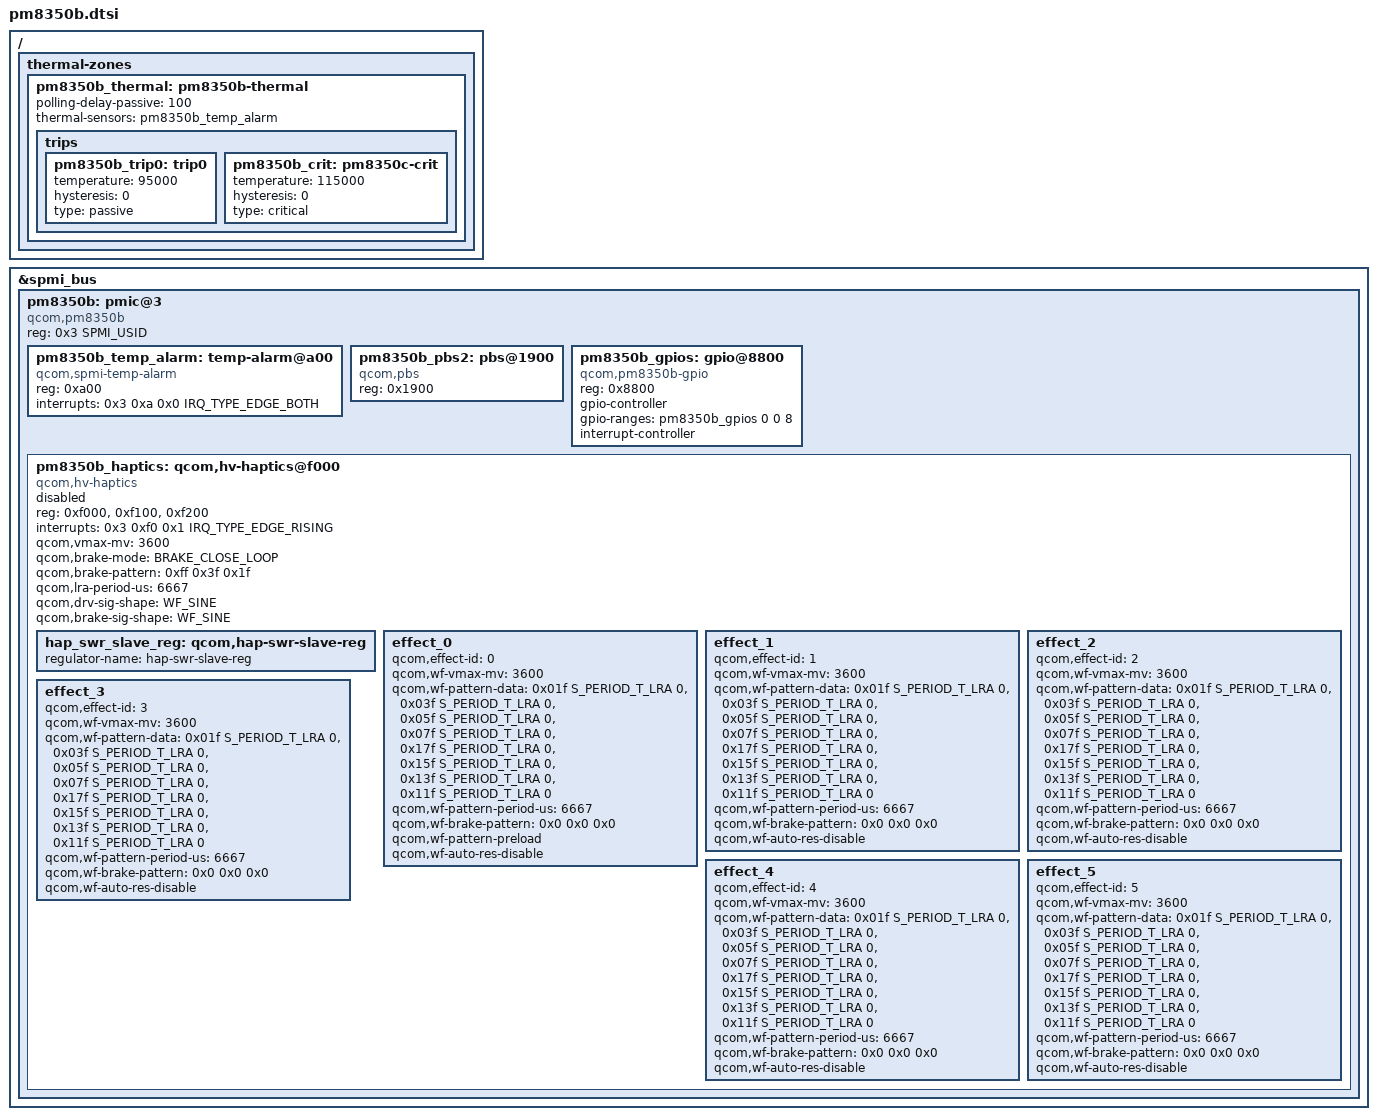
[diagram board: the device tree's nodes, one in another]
// SPDX-License-Identifier: BSD-3-Clause
/*
 * Copyright (c) 2021, Linaro Limited
 */

#include <dt-bindings/interrupt-controller/irq.h>
#include <dt-bindings/spmi/spmi.h>
#include <dt-bindings/input/qcom,hv-haptics.h>

/ {
	thermal-zones {
		pm8350b_thermal: pm8350b-thermal {
			polling-delay-passive = <100>;

			thermal-sensors = <&pm8350b_temp_alarm>;

			trips {
				pm8350b_trip0: trip0 {
					temperature = <95000>;
					hysteresis = <0>;
					type = "passive";
				};

				pm8350b_crit: pm8350c-crit {
					temperature = <115000>;
					hysteresis = <0>;
					type = "critical";
				};
			};
		};
	};
};

&spmi_bus {
	pm8350b: pmic@3 {
		compatible = "qcom,pm8350b", "qcom,spmi-pmic";
		reg = <0x3 SPMI_USID>;
		#address-cells = <1>;
		#size-cells = <0>;

		pm8350b_temp_alarm: temp-alarm@a00 {
			compatible = "qcom,spmi-temp-alarm";
			reg = <0xa00>;
			interrupts = <0x3 0xa 0x0 IRQ_TYPE_EDGE_BOTH>;
			#thermal-sensor-cells = <0>;
		};

		pm8350b_pbs2: pbs@1900 {
			compatible = "qcom,pbs";
			reg = <0x1900>;
		};

		pm8350b_gpios: gpio@8800 {
			compatible = "qcom,pm8350b-gpio", "qcom,spmi-gpio";
			reg = <0x8800>;
			gpio-controller;
			gpio-ranges = <&pm8350b_gpios 0 0 8>;
			#gpio-cells = <2>;
			interrupt-controller;
			#interrupt-cells = <2>;
		};

		pm8350b_haptics: qcom,hv-haptics@f000 {
			compatible = "qcom,hv-haptics";
			reg = <0xf000>, <0xf100>, <0xf200>;
			interrupts = <0x3 0xf0 0x1 IRQ_TYPE_EDGE_RISING>;
			interrupt-names = "fifo-empty";
			qcom,vmax-mv = <3600>;
			qcom,brake-mode = <BRAKE_CLOSE_LOOP>;
			qcom,brake-pattern = /bits/ 8 <0xff 0x3f 0x1f>;
			qcom,lra-period-us = <6667>;
			qcom,drv-sig-shape = <WF_SINE>;
			qcom,brake-sig-shape = <WF_SINE>;
			status = "disabled";

			hap_swr_slave_reg: qcom,hap-swr-slave-reg {
				regulator-name = "hap-swr-slave-reg";
			};

			effect_0 {
				/* CLICK */
				qcom,effect-id = <0>;
				qcom,wf-vmax-mv = <3600>;
				qcom,wf-pattern-data =  <0x01f  S_PERIOD_T_LRA  0>,
							<0x03f  S_PERIOD_T_LRA  0>,
							<0x05f  S_PERIOD_T_LRA  0>,
							<0x07f  S_PERIOD_T_LRA  0>,
							<0x17f  S_PERIOD_T_LRA  0>,
							<0x15f  S_PERIOD_T_LRA  0>,
							<0x13f  S_PERIOD_T_LRA  0>,
							<0x11f  S_PERIOD_T_LRA  0>;
				qcom,wf-pattern-period-us = <6667>;
				qcom,wf-brake-pattern = /bits/ 8 <0x0 0x0 0x0>;
				qcom,wf-pattern-preload;
				qcom,wf-auto-res-disable;
			};

			effect_1 {
				/* DOUBLE_CLICK */
				qcom,effect-id = <1>;
				qcom,wf-vmax-mv = <3600>;
				qcom,wf-pattern-data =  <0x01f  S_PERIOD_T_LRA  0>,
							<0x03f  S_PERIOD_T_LRA  0>,
							<0x05f  S_PERIOD_T_LRA  0>,
							<0x07f  S_PERIOD_T_LRA  0>,
							<0x17f  S_PERIOD_T_LRA  0>,
							<0x15f  S_PERIOD_T_LRA  0>,
							<0x13f  S_PERIOD_T_LRA  0>,
							<0x11f  S_PERIOD_T_LRA  0>;
				qcom,wf-pattern-period-us = <6667>;
				qcom,wf-brake-pattern = /bits/ 8 <0x0 0x0 0x0>;
				qcom,wf-auto-res-disable;
			};

			effect_2 {
				/* TICK */
				qcom,effect-id = <2>;
				qcom,wf-vmax-mv = <3600>;
				qcom,wf-pattern-data =  <0x01f  S_PERIOD_T_LRA  0>,
							<0x03f  S_PERIOD_T_LRA  0>,
							<0x05f  S_PERIOD_T_LRA  0>,
							<0x07f  S_PERIOD_T_LRA  0>,
							<0x17f  S_PERIOD_T_LRA  0>,
							<0x15f  S_PERIOD_T_LRA  0>,
							<0x13f  S_PERIOD_T_LRA  0>,
							<0x11f  S_PERIOD_T_LRA  0>;
				qcom,wf-pattern-period-us = <6667>;
				qcom,wf-brake-pattern = /bits/ 8 <0x0 0x0 0x0>;
				qcom,wf-auto-res-disable;
			};

			effect_3 {
				/* THUD */
				qcom,effect-id = <3>;
				qcom,wf-vmax-mv = <3600>;
				qcom,wf-pattern-data =  <0x01f  S_PERIOD_T_LRA  0>,
							<0x03f  S_PERIOD_T_LRA  0>,
							<0x05f  S_PERIOD_T_LRA  0>,
							<0x07f  S_PERIOD_T_LRA  0>,
							<0x17f  S_PERIOD_T_LRA  0>,
							<0x15f  S_PERIOD_T_LRA  0>,
							<0x13f  S_PERIOD_T_LRA  0>,
							<0x11f  S_PERIOD_T_LRA  0>;
				qcom,wf-pattern-period-us = <6667>;
				qcom,wf-brake-pattern = /bits/ 8 <0x0 0x0 0x0>;
				qcom,wf-auto-res-disable;
			};

			effect_4 {
				/* POP */
				qcom,effect-id = <4>;
				qcom,wf-vmax-mv = <3600>;
				qcom,wf-pattern-data =  <0x01f  S_PERIOD_T_LRA  0>,
							<0x03f  S_PERIOD_T_LRA  0>,
							<0x05f  S_PERIOD_T_LRA  0>,
							<0x07f  S_PERIOD_T_LRA  0>,
							<0x17f  S_PERIOD_T_LRA  0>,
							<0x15f  S_PERIOD_T_LRA  0>,
							<0x13f  S_PERIOD_T_LRA  0>,
							<0x11f  S_PERIOD_T_LRA  0>;
				qcom,wf-pattern-period-us = <6667>;
				qcom,wf-brake-pattern = /bits/ 8 <0x0 0x0 0x0>;
				qcom,wf-auto-res-disable;
			};

			effect_5 {
				/* HEAVY CLICK */
				qcom,effect-id = <5>;
				qcom,wf-vmax-mv = <3600>;
				qcom,wf-pattern-data =  <0x01f  S_PERIOD_T_LRA  0>,
							<0x03f  S_PERIOD_T_LRA  0>,
							<0x05f  S_PERIOD_T_LRA  0>,
							<0x07f  S_PERIOD_T_LRA  0>,
							<0x17f  S_PERIOD_T_LRA  0>,
							<0x15f  S_PERIOD_T_LRA  0>,
							<0x13f  S_PERIOD_T_LRA  0>,
							<0x11f  S_PERIOD_T_LRA  0>;
				qcom,wf-pattern-period-us = <6667>;
				qcom,wf-brake-pattern = /bits/ 8 <0x0 0x0 0x0>;
				qcom,wf-auto-res-disable;
			};
		};
	};
};
